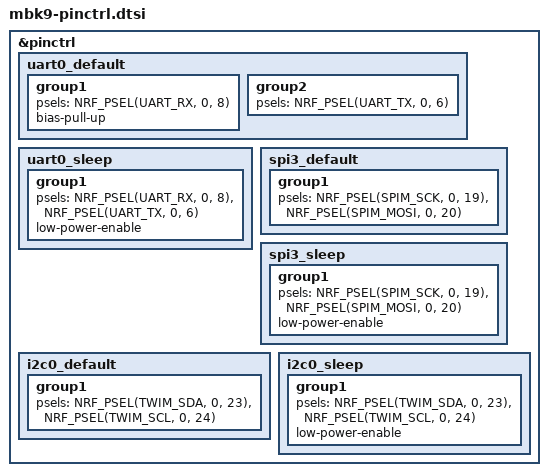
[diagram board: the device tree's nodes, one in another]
/*
 * Pin Control Configuration for MBK9 (3x3 Matrix)
 */

#include <dt-bindings/pinctrl/nrf-pinctrl.h>

&pinctrl {
    // UART Pin Configuration (GPIO 6 and 8)
    uart0_default: uart0_default {
        group1 {
            psels = <NRF_PSEL(UART_RX, 0, 8)>;
            bias-pull-up;
        };
        group2 {
            psels = <NRF_PSEL(UART_TX, 0, 6)>;
        };
    };

    uart0_sleep: uart0_sleep {
        group1 {
            psels = <NRF_PSEL(UART_RX, 0, 8)>,
                    <NRF_PSEL(UART_TX, 0, 6)>;
            low-power-enable;
        };
    };

    // SPI Pin Configuration for WS2812B (if using SPI)
    spi3_default: spi3_default {
        group1 {
            psels = <NRF_PSEL(SPIM_SCK, 0, 19)>,
                    <NRF_PSEL(SPIM_MOSI, 0, 20)>;
        };
    };

    spi3_sleep: spi3_sleep {
        group1 {
            psels = <NRF_PSEL(SPIM_SCK, 0, 19)>,
                    <NRF_PSEL(SPIM_MOSI, 0, 20)>;
            low-power-enable;
        };
    };

    // I2C Pin Configuration (if using I2C for future expansion)
    i2c0_default: i2c0_default {
        group1 {
            psels = <NRF_PSEL(TWIM_SDA, 0, 23)>,
                    <NRF_PSEL(TWIM_SCL, 0, 24)>;
        };
    };

    i2c0_sleep: i2c0_sleep {
        group1 {
            psels = <NRF_PSEL(TWIM_SDA, 0, 23)>,
                    <NRF_PSEL(TWIM_SCL, 0, 24)>;
            low-power-enable;
        };
    };
};
